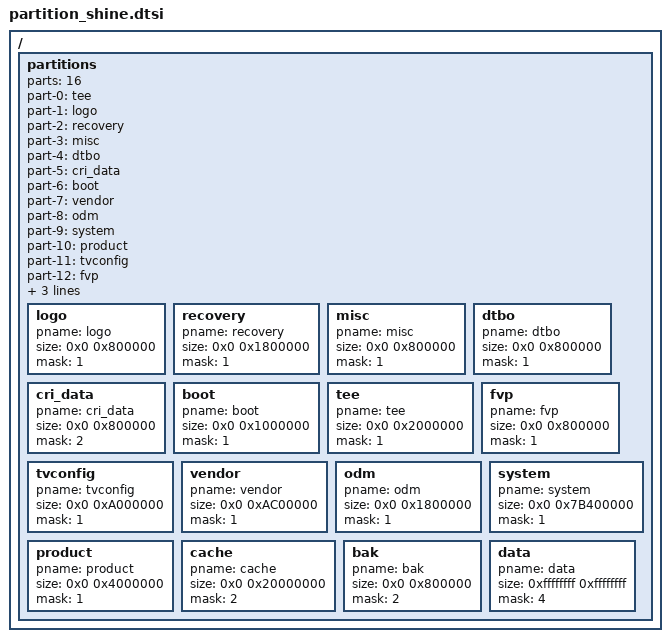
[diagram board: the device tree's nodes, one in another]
/*
 * Amlogic partition set for normal
 *
 * Copyright (c) 2017-2017 Amlogic Ltd
 *
 * This file is licensed under a dual GPLv2 or BSD license.
 *
 */

#include "firmware_system.dtsi"

/ {
    partitions: partitions{
		parts = <16>;
		part-0 = <&tee>;
		part-1 = <&logo>;
		part-2 = <&recovery>;
		part-3 = <&misc>;
		part-4 = <&dtbo>;
		part-5 = <&cri_data>;
		part-6 = <&boot>;
		part-7 = <&vendor>;
		part-8 = <&odm>;
		part-9 = <&system>;
		part-10 = <&product>;
		part-11 = <&tvconfig>;
		part-12 = <&fvp>;
		part-13 = <&cache>;
		part-14 = <&bak>;
		part-15 = <&data>;
		logo:logo{
			pname = "logo";
			size = <0x0 0x800000>;
			mask = <1>;
		};
		recovery:recovery{
			pname = "recovery";
			size = <0x0 0x1800000>;
			mask = <1>;
		};
		misc:misc{
			pname = "misc";
			size = <0x0 0x800000>;
			mask = <1>;
		};
		dtbo:dtbo{
			pname = "dtbo";
			size = <0x0 0x800000>;
			mask = <1>;
		};
		cri_data:cri_data
		{
			pname = "cri_data";
			size = <0x0 0x800000>;
			mask = <2>;
		};
		boot:boot
		{
			pname = "boot";
			size = <0x0 0x1000000>;
			mask = <1>;
		};
		tee:tee{
			pname = "tee";
			size = <0x0 0x2000000>;
			mask = <1>;
		};
		fvp:fvp{
			pname = "fvp";
			size = <0x0 0x800000>;
			mask = <1>;
		};
		tvconfig:tvconfig{
			pname = "tvconfig";
			size = <0x0 0xA000000>;
			mask = <1>;
		};
		vendor:vendor
		{
			pname = "vendor";
			size = <0x0 0xAC00000>;
			mask = <1>;
		};
		odm:odm
		{
			pname = "odm";
			size = <0x0 0x1800000>;
			mask = <1>;
		};
		system:system
		{
			pname = "system";
			size = <0x0 0x7B400000>;
			mask = <1>;
		};
		product:product{
			pname = "product";
			size = <0x0 0x4000000>;
			mask = <1>;
		};
		cache:cache
		{
			pname = "cache";
			size = <0x0 0x20000000>;
			mask = <2>;
		};
		bak:bak{
			pname = "bak";
			size = <0x0 0x800000>;
			mask = <2>;
		};
		data:data
		{
			pname = "data";
			size = <0xffffffff 0xffffffff>;
			mask = <4>;
		};
	};
};/* end of / */
